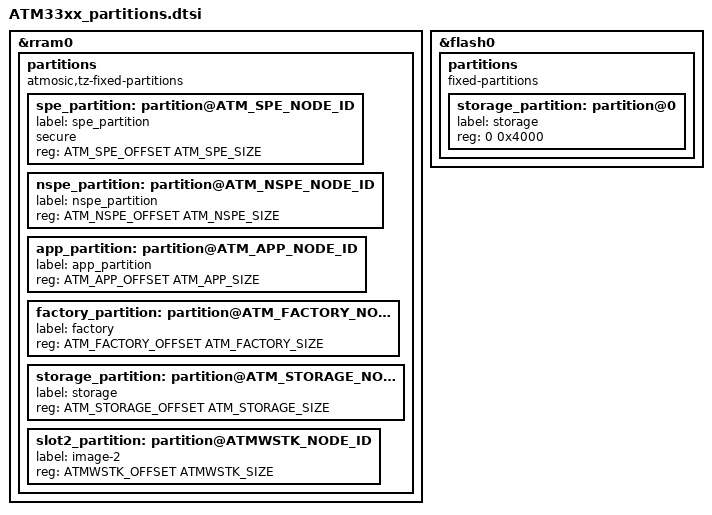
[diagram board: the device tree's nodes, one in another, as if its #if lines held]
/*
 * Copyright (c) 2021-2025 Atmosic
 *
 * SPDX-License-Identifier: Apache-2.0
 */

#include <arm/atmosic/ATM33xx_partition_defs.h>

&rram0 {
	partitions {
#if ATM_SPE_SIZE
		compatible = "atmosic,tz-fixed-partitions", "fixed-partitions";
#else
		compatible = "fixed-partitions";
#endif
		#address-cells = <1>;
		#size-cells = <1>;

#if ATM_SPE_SIZE
		spe_partition: partition@ATM_SPE_NODE_ID {
			label = "spe_partition";
			secure;
			reg = <ATM_SPE_OFFSET ATM_SPE_SIZE>;
		};
		nspe_partition: partition@ATM_NSPE_NODE_ID {
			label = "nspe_partition";
			reg = <ATM_NSPE_OFFSET ATM_NSPE_SIZE>;
		};
#endif
#if ATM_APP_SIZE
		app_partition: partition@ATM_APP_NODE_ID {
			label = "app_partition";
			reg = <ATM_APP_OFFSET ATM_APP_SIZE>;
		};
#endif
#if ATM_FACTORY_SIZE
		factory_partition: partition@ATM_FACTORY_NODE_ID {
			label = "factory";
			reg = <ATM_FACTORY_OFFSET ATM_FACTORY_SIZE>;
		};
#endif
#ifndef TEST_STORAGE_IN_FLASH
#if ATM_STORAGE_SIZE
		storage_partition: partition@ATM_STORAGE_NODE_ID {
			label = "storage";
			reg = <ATM_STORAGE_OFFSET ATM_STORAGE_SIZE>;
		};
#endif
#endif
#if ATMWSTK_SIZE
		slot2_partition: partition@ATMWSTK_NODE_ID {
			label = "image-2";
			reg = <ATMWSTK_OFFSET ATMWSTK_SIZE>;
		};
#endif
	};
};

#ifdef TEST_STORAGE_IN_FLASH
// flash driver testing, allocate a storage partition at the beginning of flash
&flash0 {
	partitions {
		#address-cells = <1>;
		#size-cells = <1>;
		compatible = "fixed-partitions";
		storage_partition: partition@0 {
			label = "storage";
			reg = <0 0x4000>;
		};
	};
};
#endif
